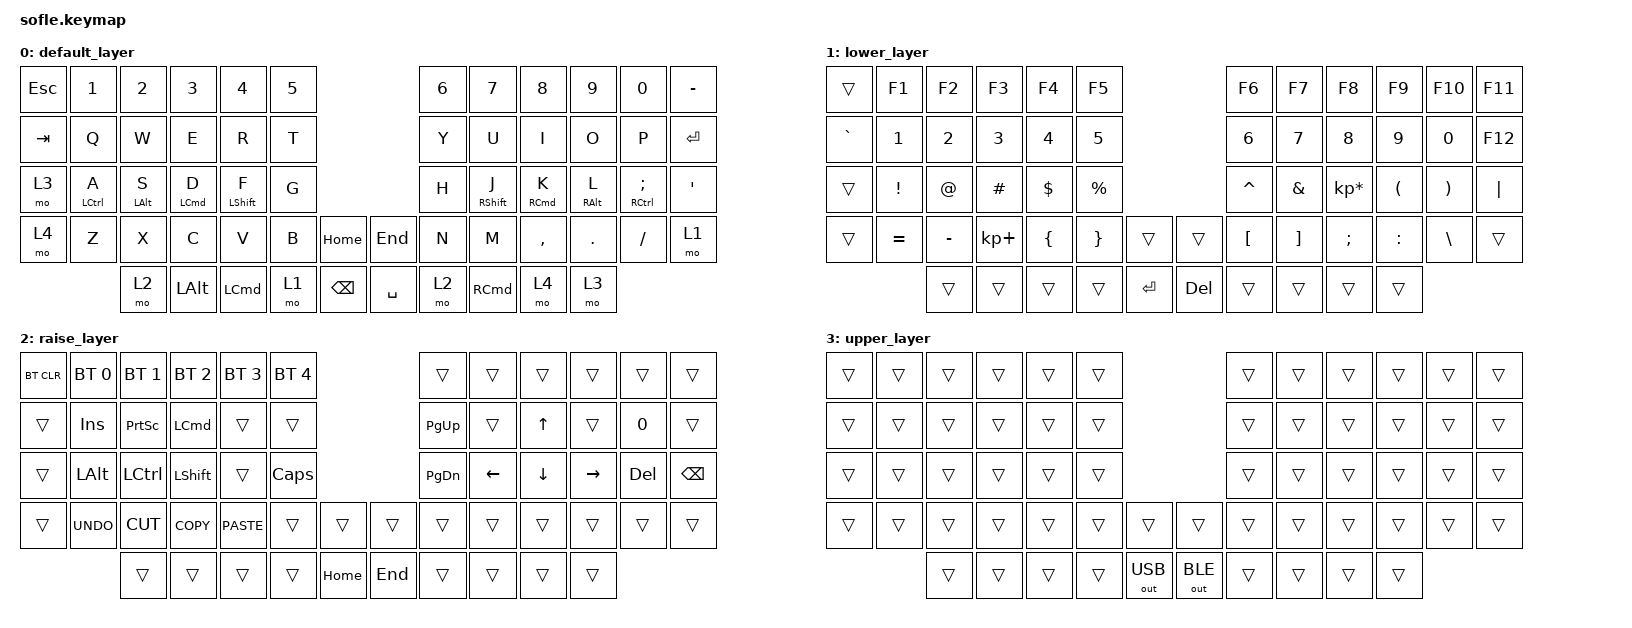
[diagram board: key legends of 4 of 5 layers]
/*
 * Copyright (c) 2020 The ZMK Contributors
 *
 * SPDX-License-Identifier: MIT
 */

#include <behaviors.dtsi>
#include <dt-bindings/zmk/keys.h>
#include <dt-bindings/zmk/bt.h>
#include <dt-bindings/zmk/modifiers.h>
#include <dt-bindings/zmk/outputs.h>
#include <dt-bindings/zmk/ext_power.h>

/ {
    behaviors {
        hm: homerow_mods {
            compatible = "zmk,behavior-hold-tap";
            label = "HOMEROW_MODS";
            #binding-cells = <2>;
            tapping_term_ms = <175>;
            flavor = "tap-preferred";
            bindings = <&kp>, <&kp>;
        };
    };

    keymap {
        compatible = "zmk,keymap";

        default_layer {
// ------------------------------------------------------------------------------------------------------------
// |  `    |  1  |  2  |  3   |  4   |  5   |                   |  6   |  7    |  8    |  9   |   0   |       |
// |  ESC  |  Q  |  W  |  E   |  R   |  T   |                   |  Y   |  U    |  I    |  O   |   P   | BKSPC |
// |  TAB  |  A  |  S  |  D   |  F   |  G   |                   |  H   |  J    |  K    |  L   |   ;   |   '   |
// | SHIFT |  Z  |  X  |  C   |  V   |  B   |  MUTE  |  |       |  N   |  M    |  ,    |  .   |   /   | SHIFT |
//               | GUI | ALT  | CTRL | LOWER|  ENTER |  | SPACE | RAISE| CTRL  | ALT   | GUI  |
            bindings = <
&kp ESC   &kp N1      &kp N2     &kp N3     &kp N4      &kp N5                       &kp N6    &kp N7      &kp N8      &kp N9     &kp N0         &kp MINUS
&kp TAB   &kp Q       &kp W      &kp E      &kp R       &kp T                        &kp Y     &kp U       &kp I       &kp O      &kp P          &kp RET
&mo 3     &hm LCTRL A &hm LALT S &hm LCMD D &hm LSHFT F &kp G                        &kp H     &hm RSHFT J &hm RCMD K  &hm RALT L &hm RCTRL SEMI &kp SQT
&mo 4     &kp Z       &kp X      &kp C      &kp V       &kp B  &kp HOME    &kp END   &kp N     &kp M       &kp COMMA   &kp DOT    &kp FSLH       &mo 1
                      &mo 2      &kp LALT   &kp LCMD    &mo 1  &kp BSPC    &kp SPACE &mo 2     &kp RCMD    &mo 4       &mo 3 
            >;

            sensor-bindings = <&inc_dec_kp DEL BSPC &inc_dec_kp PG_UP PG_DN>;
        };

        lower_layer {
// ------------------------------------------------------------------------------------------------------------
// |       |  F1 |  F2 |  F3  |  F4  |  F5  |                   |  F6  |  F7   |  F8   |  F9  |  F10  |  F11  |
// | `     |   1 |   2 |   3  |   4  |   5  |                   |   6  |   7   |   8   |   9  |    0  |  F12  |
// |       |  !  |  @  |  #   |  $   |  %   |                   |  ^   |  &    |  *    |  (   |   )   |   |   |
// |       |  =  |  -  |  +   |  {   |  }   |        |  |       |  [   |  ]    |  ;    |  :   |   \   |       |
//               |     |      |      |      |        |  |       |      |       |       |      |
            bindings = <
&trans    &kp F1    &kp F2    &kp F3      &kp F4    &kp F5                     &kp F6    &kp F7    &kp F8          &kp F9     &kp F10   &kp F11
&kp GRAVE &kp N1    &kp N2    &kp N3      &kp N4    &kp N5                     &kp N6    &kp N7    &kp N8          &kp N9     &kp N0    &kp F12
&trans    &kp EXCL  &kp AT    &kp HASH    &kp DLLR  &kp PRCNT                  &kp CARET &kp AMPS  &kp KP_MULTIPLY &kp LPAR   &kp RPAR  &kp PIPE
&trans    &kp EQUAL &kp MINUS &kp KP_PLUS &kp LBRC  &kp RBRC  &trans   &trans  &kp LBKT  &kp RBKT  &kp SEMI        &kp COLON  &kp BSLH  &trans
                      &trans    &trans    &trans    &trans   &kp RET   &kp DEL &trans    &trans    &trans      &trans
            >;

            sensor-bindings = <&inc_dec_kp PG_DN PG_UP &inc_dec_kp PG_DN PG_UP>;
        };

        raise_layer {
// ------------------------------------------------------------------------------------------------------------
// |BTCLR| BT1  | BT2  |  BT3  |  BT4  |  BT5 |                |      |      |       |      |       |       |
// |     | INS  | PSCR | GUI   |       |      |                | PGUP |      |   ^   |      |       |       |
// |     | ALT  | CTRL | SHIFT |       | CAPS |                | PGDN |   <- |   v   |  ->  |  DEL  | BKSPC |
// |     | UNDO | CUT  | COPY  | PASTE |      |      |  |      |      |      |       |      |       |       |
//              |      |       |       |      |      |  |      |      |      |       |      |
            bindings = <
&bt BT_CLR &bt BT_SEL 0 &bt BT_SEL 1 &bt BT_SEL 2 &bt BT_SEL 3 &bt BT_SEL 4                &trans    &trans    &trans    &trans    &trans    &trans
&trans     &kp INS      &kp PSCRN    &kp LCMD     &trans       &trans                      &kp PG_UP &trans    &kp UP    &trans    &kp N0    &trans
&trans     &kp LALT     &kp LCTRL    &kp LSHFT    &trans       &kp CLCK                    &kp PG_DN &kp LEFT  &kp DOWN  &kp RIGHT &kp DEL   &kp BSPC
&trans     &kp K_UNDO   &kp K_CUT    &kp K_COPY   &kp K_PASTE  &trans   &trans     &trans  &trans    &trans    &trans    &trans    &trans    &trans
                        &trans       &trans       &trans       &trans   &kp HOME   &kp END &trans    &trans    &trans    &trans
            >;

            sensor-bindings = <&inc_dec_kp DOWN UP &inc_dec_kp PG_DN PG_UP>;
        };

        upper_layer {
// ------------------------------------------------------------------------------------------------------------
// |     |      |      |       |       |      |                |      |      |       |      |       |       |
// |     |      |      |       |       |      |                |      |      |   ^   |      |       |       |
// |     |      |      |       |       |      |                |      |   <- |   v   |  ->  |       |       |
// |     |      |      |       |       |      |      |  |      |      |      |       |      |       |       |
//              |      |       |       |      |  USB |  | BLE  |      |      |       |      |
            bindings = <
&trans     &trans      &trans      &trans      &trans      &trans                               &trans    &trans    &trans    &trans     &trans     &trans
&trans     &trans      &trans      &trans      &trans      &trans                               &trans    &trans    &trans    &trans     &trans     &trans
&trans     &trans      &trans      &trans      &trans      &trans                               &trans    &trans    &trans    &trans     &trans     &trans
&trans     &trans      &trans      &trans      &trans      &trans  &trans          &trans       &trans    &trans    &trans    &trans     &trans     &trans
                       &trans      &trans      &trans      &trans  &out OUT_USB    &out OUT_BLE &trans    &trans    &trans    &trans
            >;

            sensor-bindings = <&inc_dec_kp RIGHT LEFT &inc_dec_kp PG_DN PG_UP>;
                    };

        top_layer {
// ------------------------------------------------------------------------------------------------------------
// |BTCLR| BT1  | BT2  |  BT3  |  BT4  |  BT5 |                |      |      |       |      |       |       |
// |     | INS  | PSCR | GUI   |       |      |                | PGUP |      |   ^   |      |       |       |
// |     | ALT  | CTRL | SHIFT |       | CAPS |                | PGDN |   <- |   v   |  ->  |  DEL  | BKSPC |
// |     | UNDO | CUT  | COPY  | PASTE |      |      |  |      |      |      |       |      |       |       |
//              |      |       |       |      |      |  |      |      |      |       |      |
            bindings = <
&trans     &trans      &trans      &trans      &trans      &trans                               &trans            &trans    &trans    &trans     &trans     &trans
&trans     &trans      &trans      &trans      &trans      &trans                               &ext_power EP_OFF &trans    &trans    &trans     &trans     &trans     &trans
&trans     &trans      &trans      &trans      &trans      &trans                               &ext_power EP_ON  &trans    &trans    &trans     &trans     &trans
&trans     &trans      &trans      &trans      &trans      &trans  &trans           &trans      &ext_power EP_TOG &trans    &trans    &trans     &trans     &trans
                       &trans      &trans      &trans      &trans  &kp LG(V)        &kp LG(C)   &kp LG(X)    &trans      &trans    &trans
            >;

            sensor-bindings = <&inc_dec_kp TAB LS(TAB) &inc_dec_kp PG_DN PG_UP>;
        };
    };
};
